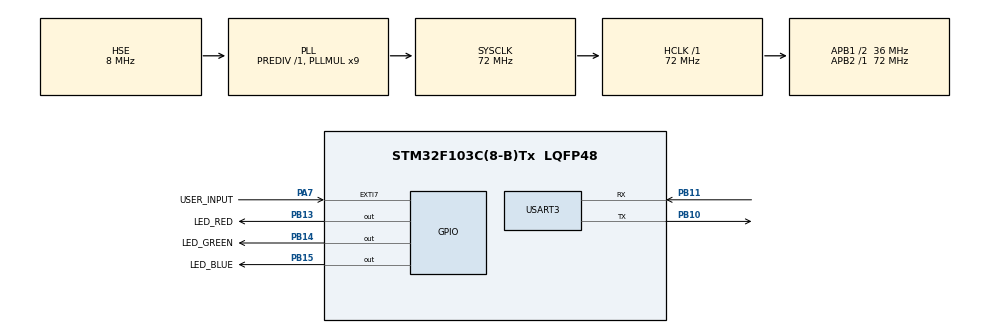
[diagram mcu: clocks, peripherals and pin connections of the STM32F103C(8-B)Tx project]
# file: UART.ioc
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Mcu.Family=STM32F1
Mcu.Name=STM32F103C(8-B)Tx
Mcu.Package=LQFP48
NVIC.EXTI9_5_IRQn=true\:1\:0\:true\:false\:true\:true
NVIC.PriorityGroup=NVIC_PRIORITYGROUP_4
NVIC.RCC_IRQn=true\:0\:0\:false\:false\:true\:true
NVIC.TIM2_IRQn=true\:3\:0\:true\:false\:true\:true
NVIC.USART3_IRQn=true\:2\:0\:true\:false\:true\:true
PA13.Mode=Serial_Wire
PA13.Signal=SYS_JTMS-SWDIO
PA14.Mode=Serial_Wire
PA14.Signal=SYS_JTCK-SWCLK
PA7.GPIO_Label=USER_INPUT
PA7.Signal=GPXTI7
PB10.Mode=Asynchronous
PB10.Signal=USART3_TX
PB11.Mode=Asynchronous
PB11.Signal=USART3_RX
PB13.GPIO_Label=LED_RED
PB13.Signal=GPIO_Output
PB14.GPIO_Label=LED_GREEN
PB14.Signal=GPIO_Output
PB15.GPIO_Label=LED_BLUE
PB15.Signal=GPIO_Output
PD0-OSC_IN.Mode=HSE-External-Oscillator
PD0-OSC_IN.Signal=RCC_OSC_IN
PD1-OSC_OUT.Mode=HSE-External-Oscillator
PD1-OSC_OUT.Signal=RCC_OSC_OUT
ProjectManager.HeapSize=0x200
ProjectManager.StackSize=0x400
ProjectManager.TargetToolchain=MDK-ARM V5
RCC.AHBFreq_Value=72000000
RCC.APB1CLKDivider=RCC_HCLK_DIV2
RCC.APB1Freq_Value=36000000
RCC.APB1TimFreq_Value=72000000
RCC.APB2Freq_Value=72000000
RCC.APB2TimFreq_Value=72000000
RCC.HCLKFreq_Value=72000000
RCC.PLLMUL=RCC_PLL_MUL9
RCC.PLLSourceVirtual=RCC_PLLSOURCE_HSE
RCC.SYSCLKFreq_VALUE=72000000
RCC.SYSCLKSource=RCC_SYSCLKSOURCE_PLLCLK
RCC.USBFreq_Value=72000000
USART3.VirtualMode=VM_ASYNC
VP_TIM2_VS_ClockSourceINT.Mode=Internal
board=uartITEx

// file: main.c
/**
  ******************************************************************************
  * File Name          : main.c
  * Description        : Main program body
  ******************************************************************************
  ** This notice applies to any and all portions of this file
  * that are not between comment pairs USER CODE BEGIN and
  * USER CODE END. Other portions of this file, whether
  * inserted by the user or by software development tools
  * are owned by their respective copyright owners.
  *
  * COPYRIGHT(c) 2019 STMicroelectronics
  *
  * Redistribution and use in source and binary forms, with or without modification,
  * are permitted provided that the following conditions are met:
  *   1. Redistributions of source code must retain the above copyright notice,
  *      this list of conditions and the following disclaimer.
  *   2. Redistributions in binary form must reproduce the above copyright notice,
  *      this list of conditions and the following disclaimer in the documentation
  *      and/or other materials provided with the distribution.
  *   3. Neither the name of STMicroelectronics nor the names of its contributors
  *      may be used to endorse or promote products derived from this software
  *      without specific prior written permission.
  *
  * THIS SOFTWARE IS PROVIDED BY THE COPYRIGHT HOLDERS AND CONTRIBUTORS "AS IS"
  * AND ANY EXPRESS OR IMPLIED WARRANTIES, INCLUDING, BUT NOT LIMITED TO, THE
  * IMPLIED WARRANTIES OF MERCHANTABILITY AND FITNESS FOR A PARTICULAR PURPOSE ARE
  * DISCLAIMED. IN NO EVENT SHALL THE COPYRIGHT HOLDER OR CONTRIBUTORS BE LIABLE
  * FOR ANY DIRECT, INDIRECT, INCIDENTAL, SPECIAL, EXEMPLARY, OR CONSEQUENTIAL
  * DAMAGES (INCLUDING, BUT NOT LIMITED TO, PROCUREMENT OF SUBSTITUTE GOODS OR
  * SERVICES; LOSS OF USE, DATA, OR PROFITS; OR BUSINESS INTERRUPTION) HOWEVER
  * CAUSED AND ON ANY THEORY OF LIABILITY, WHETHER IN CONTRACT, STRICT LIABILITY,
  * OR TORT (INCLUDING NEGLIGENCE OR OTHERWISE) ARISING IN ANY WAY OUT OF THE USE
  * OF THIS SOFTWARE, EVEN IF ADVISED OF THE POSSIBILITY OF SUCH DAMAGE.
  *
  ******************************************************************************
  */
#include "main.h"
#include "stm32f1xx_hal.h"

TIM_HandleTypeDef htim2;

UART_HandleTypeDef huart3;

/* USER CODE BEGIN PV */
/* Private variables ---------------------------------------------------------*/

/* USER CODE END PV */

void SystemClock_Config(void);
static void MX_GPIO_Init(void);
static void MX_TIM2_Init(void);
static void MX_USART3_UART_Init(void);

/* USER CODE BEGIN PFP */
/* Private function prototypes -----------------------------------------------*/

/* USER CODE END PFP */

/* USER CODE BEGIN 0 */
uint32_t dataLen = 0;
uint8_t buffer[20] = {0};
/* USER CODE END 0 */

int main(void)
{

  /* MCU Configuration----------------------------------------------------------*/

  /* Reset of all peripherals, Initializes the Flash interface and the Systick. */
  HAL_Init();

  /* Configure the system clock */
  SystemClock_Config();

  /* Initialize all configured peripherals */
  MX_GPIO_Init();
  MX_TIM2_Init();
  MX_USART3_UART_Init();

  /* Infinite loop */
  while (1)
  {

  /* USER CODE BEGIN 3 */
		if(dataLen > 10)
		{
			HAL_UART_Transmit(&huart3, (uint8_t *)buffer, dataLen, 100);
			dataLen = 0;
		}
  }
  /* USER CODE END 3 */

}

/** System Clock Configuration
*/
void SystemClock_Config(void)
{

  RCC_OscInitTypeDef RCC_OscInitStruct;
  RCC_ClkInitTypeDef RCC_ClkInitStruct;

    /**Initializes the CPU, AHB and APB busses clocks
    */
  RCC_OscInitStruct.OscillatorType = RCC_OSCILLATORTYPE_HSE;
  RCC_OscInitStruct.HSEState = RCC_HSE_ON;
  RCC_OscInitStruct.HSEPredivValue = RCC_HSE_PREDIV_DIV1;
  RCC_OscInitStruct.HSIState = RCC_HSI_ON;
  RCC_OscInitStruct.PLL.PLLState = RCC_PLL_ON;
  RCC_OscInitStruct.PLL.PLLSource = RCC_PLLSOURCE_HSE;
  RCC_OscInitStruct.PLL.PLLMUL = RCC_PLL_MUL9;
  if (HAL_RCC_OscConfig(&RCC_OscInitStruct) != HAL_OK)
  {
    _Error_Handler(__FILE__, __LINE__);
  }

    /**Initializes the CPU, AHB and APB busses clocks
    */
  RCC_ClkInitStruct.ClockType = RCC_CLOCKTYPE_HCLK|RCC_CLOCKTYPE_SYSCLK
                              |RCC_CLOCKTYPE_PCLK1|RCC_CLOCKTYPE_PCLK2;
  RCC_ClkInitStruct.SYSCLKSource = RCC_SYSCLKSOURCE_PLLCLK;
  RCC_ClkInitStruct.AHBCLKDivider = RCC_SYSCLK_DIV1;
  RCC_ClkInitStruct.APB1CLKDivider = RCC_HCLK_DIV2;
  RCC_ClkInitStruct.APB2CLKDivider = RCC_HCLK_DIV1;

  if (HAL_RCC_ClockConfig(&RCC_ClkInitStruct, FLASH_LATENCY_2) != HAL_OK)
  {
    _Error_Handler(__FILE__, __LINE__);
  }

    /**Configure the Systick interrupt time
    */
  HAL_SYSTICK_Config(HAL_RCC_GetHCLKFreq()/1000);

    /**Configure the Systick
    */
  HAL_SYSTICK_CLKSourceConfig(SYSTICK_CLKSOURCE_HCLK);

  /* SysTick_IRQn interrupt configuration */
  HAL_NVIC_SetPriority(SysTick_IRQn, 0, 0);
}

/* TIM2 init function */
static void MX_TIM2_Init(void)
{

  TIM_ClockConfigTypeDef sClockSourceConfig;
  TIM_MasterConfigTypeDef sMasterConfig;

  htim2.Instance = TIM2;
  htim2.Init.Prescaler = 0;
  htim2.Init.CounterMode = TIM_COUNTERMODE_UP;
  htim2.Init.Period = 0;
  htim2.Init.ClockDivision = TIM_CLOCKDIVISION_DIV1;
  htim2.Init.AutoReloadPreload = TIM_AUTORELOAD_PRELOAD_DISABLE;
  if (HAL_TIM_Base_Init(&htim2) != HAL_OK)
  {
    _Error_Handler(__FILE__, __LINE__);
  }

  sClockSourceConfig.ClockSource = TIM_CLOCKSOURCE_INTERNAL;
  if (HAL_TIM_ConfigClockSource(&htim2, &sClockSourceConfig) != HAL_OK)
  {
    _Error_Handler(__FILE__, __LINE__);
  }

  sMasterConfig.MasterOutputTrigger = TIM_TRGO_RESET;
  sMasterConfig.MasterSlaveMode = TIM_MASTERSLAVEMODE_DISABLE;
  if (HAL_TIMEx_MasterConfigSynchronization(&htim2, &sMasterConfig) != HAL_OK)
  {
    _Error_Handler(__FILE__, __LINE__);
  }

}

/* USART3 init function */
static void MX_USART3_UART_Init(void)
{

  huart3.Instance = USART3;
  huart3.Init.BaudRate = 115200;
  huart3.Init.WordLength = UART_WORDLENGTH_8B;
  huart3.Init.StopBits = UART_STOPBITS_1;
  huart3.Init.Parity = UART_PARITY_NONE;
  huart3.Init.Mode = UART_MODE_TX_RX;
  huart3.Init.HwFlowCtl = UART_HWCONTROL_NONE;
  huart3.Init.OverSampling = UART_OVERSAMPLING_16;
  if (HAL_UART_Init(&huart3) != HAL_OK)
  {
    _Error_Handler(__FILE__, __LINE__);
  }
	__HAL_UART_ENABLE_IT(&huart3, UART_IT_RXNE);
}

/** Configure pins as
        * Analog
        * Input
        * Output
        * EVENT_OUT
        * EXTI
*/
static void MX_GPIO_Init(void)
{

  GPIO_InitTypeDef GPIO_InitStruct;

  /* GPIO Ports Clock Enable */
  __HAL_RCC_GPIOD_CLK_ENABLE();
  __HAL_RCC_GPIOA_CLK_ENABLE();
  __HAL_RCC_GPIOB_CLK_ENABLE();

  /*Configure GPIO pin Output Level */
  HAL_GPIO_WritePin(GPIOB, LED_RED_Pin|LED_GREEN_Pin|LED_BLUE_Pin, GPIO_PIN_RESET);

  /*Configure GPIO pin : USER_INPUT_Pin */
  GPIO_InitStruct.Pin = USER_INPUT_Pin;
  GPIO_InitStruct.Mode = GPIO_MODE_IT_RISING;
  GPIO_InitStruct.Pull = GPIO_NOPULL;
  HAL_GPIO_Init(USER_INPUT_GPIO_Port, &GPIO_InitStruct);

  /*Configure GPIO pins : LED_RED_Pin LED_GREEN_Pin LED_BLUE_Pin */
  GPIO_InitStruct.Pin = LED_RED_Pin|LED_GREEN_Pin|LED_BLUE_Pin;
  GPIO_InitStruct.Mode = GPIO_MODE_OUTPUT_PP;
  GPIO_InitStruct.Speed = GPIO_SPEED_FREQ_LOW;
  HAL_GPIO_Init(GPIOB, &GPIO_InitStruct);

  /* EXTI interrupt init*/
  HAL_NVIC_SetPriority(EXTI9_5_IRQn, 1, 0);
  HAL_NVIC_EnableIRQ(EXTI9_5_IRQn);

}

void _Error_Handler(char * file, int line)
{
  while(1)
  {
  }
}

/************************ (C) COPYRIGHT STMicroelectronics *****END OF FILE****/
